VERSION ""

NS_ :

BS_:

BU_: Host KincoDrive

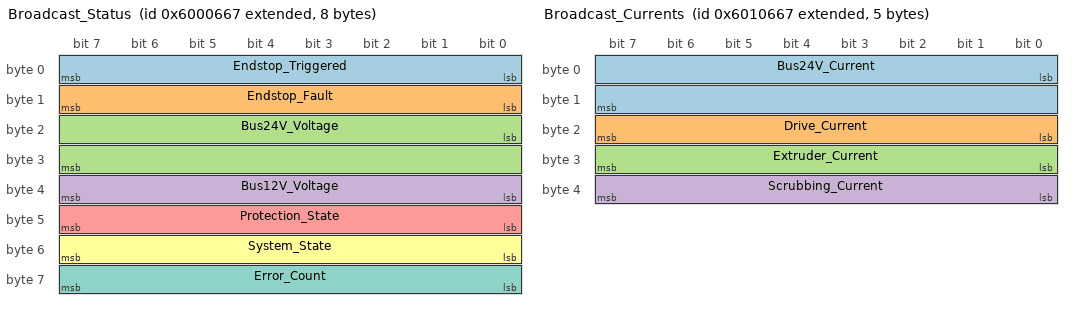
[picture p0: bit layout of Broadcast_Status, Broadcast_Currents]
BO_ 2248148583 Broadcast_Status: 8 KincoDrive
 SG_ Endstop_Triggered : 0|8@1+ (1,0) [0|63] "" Host
 SG_ Endstop_Fault : 8|8@1+ (1,0) [0|63] "" Host
 SG_ Bus24V_Voltage : 16|16@1+ (0.1,0) [0|6553.5] "V" Host
 SG_ Bus12V_Voltage : 32|8@1+ (0.1,0) [0|25.5] "V" Host
 SG_ Protection_State : 40|8@1+ (1,0) [0|255] "" Host
 SG_ System_State : 48|8@1+ (1,0) [0|3] "" Host
 SG_ Error_Count : 56|8@1+ (1,0) [0|16] "" Host

BO_ 2248214119 Broadcast_Currents: 5 KincoDrive
 SG_ Bus24V_Current : 0|16@1+ (0.1,0) [0|6553.5] "A" Host
 SG_ Drive_Current : 16|8@1+ (0.1,0) [0|25.5] "A" Host
 SG_ Extruder_Current : 24|8@1+ (0.1,0) [0|25.5] "A" Host
 SG_ Scrubbing_Current : 32|8@1+ (0.1,0) [0|25.5] "A" Host

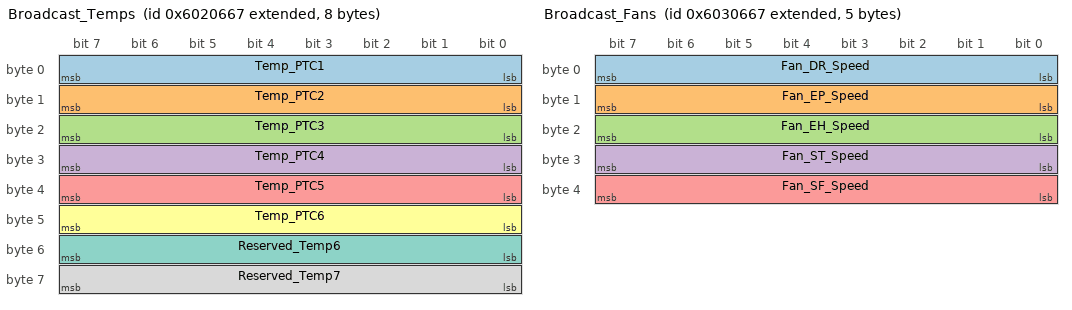
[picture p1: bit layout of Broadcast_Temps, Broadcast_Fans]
BO_ 2248279655 Broadcast_Temps: 8 KincoDrive
 SG_ Temp_PTC1 : 0|8@1+ (1,-40) [-40|215] "degC" Host
 SG_ Temp_PTC2 : 8|8@1+ (1,-40) [-40|215] "degC" Host
 SG_ Temp_PTC3 : 16|8@1+ (1,-40) [-40|215] "degC" Host
 SG_ Temp_PTC4 : 24|8@1+ (1,-40) [-40|215] "degC" Host
 SG_ Temp_PTC5 : 32|8@1+ (1,-40) [-40|215] "degC" Host
 SG_ Temp_PTC6 : 40|8@1+ (1,-40) [-40|215] "degC" Host
 SG_ Reserved_Temp6 : 48|8@1+ (1,0) [0|0] "" Host
 SG_ Reserved_Temp7 : 56|8@1+ (1,0) [0|0] "" Host

BO_ 2248345191 Broadcast_Fans: 5 KincoDrive
 SG_ Fan_DR_Speed : 0|8@1+ (1,0) [0|100] "%" Host
 SG_ Fan_EP_Speed : 8|8@1+ (1,0) [0|100] "%" Host
 SG_ Fan_EH_Speed : 16|8@1+ (1,0) [0|100] "%" Host
 SG_ Fan_ST_Speed : 24|8@1+ (1,0) [0|100] "%" Host
 SG_ Fan_SF_Speed : 32|8@1+ (1,0) [0|100] "%" Host

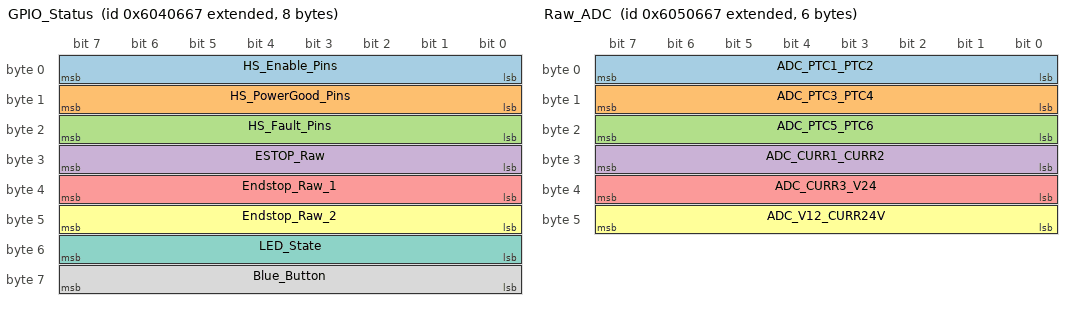
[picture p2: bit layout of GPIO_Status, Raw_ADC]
BO_ 2248410727 GPIO_Status: 8 KincoDrive
 SG_ HS_Enable_Pins : 0|8@1+ (1,0) [0|15] "" Host
 SG_ HS_PowerGood_Pins : 8|8@1+ (1,0) [0|7] "" Host
 SG_ HS_Fault_Pins : 16|8@1+ (1,0) [0|7] "" Host
 SG_ ESTOP_Raw : 24|8@1+ (1,0) [0|7] "" Host
 SG_ Endstop_Raw_1 : 32|8@1+ (1,0) [0|255] "" Host
 SG_ Endstop_Raw_2 : 40|8@1+ (1,0) [0|1] "" Host
 SG_ LED_State : 48|8@1+ (1,0) [0|1] "" Host
 SG_ Blue_Button : 56|8@1+ (1,0) [0|1] "" Host

BO_ 2248476263 Raw_ADC: 6 KincoDrive
 SG_ ADC_PTC1_PTC2 : 0|8@1+ (1,0) [0|255] "" Host
 SG_ ADC_PTC3_PTC4 : 8|8@1+ (1,0) [0|255] "" Host
 SG_ ADC_PTC5_PTC6 : 16|8@1+ (1,0) [0|255] "" Host
 SG_ ADC_CURR1_CURR2 : 24|8@1+ (1,0) [0|255] "" Host
 SG_ ADC_CURR3_V24 : 32|8@1+ (1,0) [0|255] "" Host
 SG_ ADC_V12_CURR24V : 40|8@1+ (1,0) [0|255] "" Host

CM_ BU_ KincoDrive "KincoDrive Control Module V5.4 - Device ID 0x0667 - TEST MODE (broadcast only)";
CM_ BU_ Host "Host controller / CAN analyzer";
CM_ BO_ 2248148583 "System status: endstops, bus voltages, protection state, system state, error count. Period: 500ms.";
CM_ BO_ 2248214119 "Current measurements: 24V bus and per-module high-side currents. Period: 500ms.";
CM_ BO_ 2248279655 "Temperatures: 6 PTC thermistors. Wire encoding: value = degC + 40. Period: 500ms.";
CM_ BO_ 2248345191 "Fan speeds: tachometer percentage of max RPM. Period: 500ms.";
CM_ BO_ 2248410727 "Raw GPIO status: HS enable/PG/fault pins, ESTOP, endstop raw states, LED, button. Period: 500ms.";
CM_ BO_ 2248476263 "Raw ADC: 12 channels packed as 4-bit nibbles (12-bit >> 8). Period: 500ms.";
CM_ SG_ 2248148583 Endstop_Triggered "Bit0=EH_Top, Bit1=EH_Bot, Bit2=EP_Top, Bit3=EP_Bot, Bit4=SC_Top, Bit5=ESTOP";
CM_ SG_ 2248148583 Endstop_Fault "Same bit layout. 1=wiring fault detected.";
CM_ SG_ 2248148583 Protection_State "Bits[1:0]=Drive_OC, [3:2]=Ext_OC, [5:4]=Scrub_OC, [7:6]=OV_state";
CM_ SG_ 2248148583 System_State "0=NORMAL, 1=WARNING, 2=ERROR, 3=RECOVERY";
CM_ SG_ 2248410727 HS_Enable_Pins "Bit0=DR_EN, Bit1=E_EN, Bit2=SC_EN, Bit3=VBUCK_CTRL";
CM_ SG_ 2248410727 HS_PowerGood_Pins "Bit0=DR_PG, Bit1=E_PG, Bit2=SC_PG (1=power good)";
CM_ SG_ 2248410727 HS_Fault_Pins "Bit0=DR_FT, Bit1=E_FT, Bit2=SC_FT (1=fault active)";
CM_ SG_ 2248410727 ESTOP_Raw "Bit0=NO_pin, Bit1=NC_pin, Bit2=debounced_state";
CM_ SG_ 2248410727 Endstop_Raw_1 "Bit0=EH_H_NO, Bit1=EH_H_NC, Bit2=EH_L_NO, Bit3=EP_H_NO, Bit4=EP_H_NC, Bit5=EP_L_NO, Bit6=EP_L_NC, Bit7=SC_H_NO";
CM_ SG_ 2248410727 Endstop_Raw_2 "Bit0=SC_H_NC";
CM_ SG_ 2248476263 ADC_PTC1_PTC2 "Hi nibble=PTC1, Lo nibble=PTC2 (raw ADC >> 8)";
CM_ SG_ 2248476263 ADC_PTC3_PTC4 "Hi nibble=PTC3, Lo nibble=PTC4 (raw ADC >> 8)";
CM_ SG_ 2248476263 ADC_PTC5_PTC6 "Hi nibble=PTC5, Lo nibble=PTC6 (raw ADC >> 8)";
CM_ SG_ 2248476263 ADC_CURR1_CURR2 "Hi nibble=CURR_MON_1, Lo nibble=CURR_MON_2 (raw ADC >> 8)";
CM_ SG_ 2248476263 ADC_CURR3_V24 "Hi nibble=CURR_MON_3, Lo nibble=VADC_24 (raw ADC >> 8)";
CM_ SG_ 2248476263 ADC_V12_CURR24V "Hi nibble=VADC_12, Lo nibble=CURR_MON_24V (raw ADC >> 8)";

BA_DEF_  "BusType" STRING ;
BA_DEF_ BO_  "GenMsgCycleTime" INT 0 10000;
BA_DEF_DEF_  "BusType" "CAN";
BA_DEF_DEF_  "GenMsgCycleTime" 0;

BA_ "GenMsgCycleTime" BO_ 2248148583 500;
BA_ "GenMsgCycleTime" BO_ 2248214119 500;
BA_ "GenMsgCycleTime" BO_ 2248279655 500;
BA_ "GenMsgCycleTime" BO_ 2248345191 500;
BA_ "GenMsgCycleTime" BO_ 2248410727 500;
BA_ "GenMsgCycleTime" BO_ 2248476263 500;

VAL_ 2248148583 System_State 0 "NORMAL" 1 "WARNING" 2 "ERROR" 3 "RECOVERY" ;
